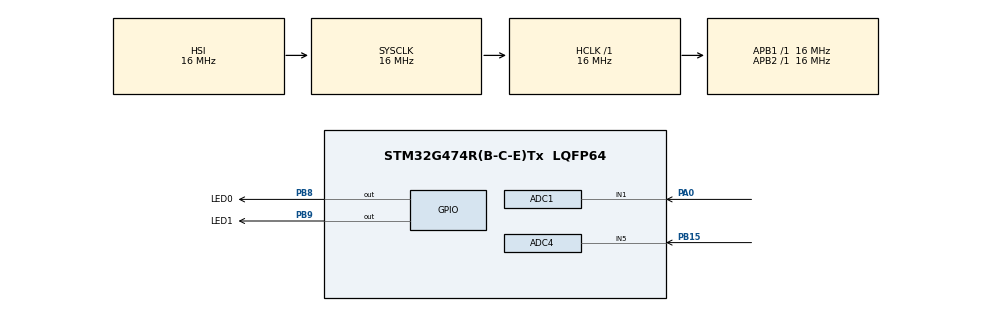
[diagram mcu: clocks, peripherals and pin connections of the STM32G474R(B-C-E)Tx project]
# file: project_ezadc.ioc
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ADC1.Channel-0\#ChannelRegularConversion=ADC_CHANNEL_1
ADC1.NbrOfConversionFlag=1
ADC1.OffsetNumber-0\#ChannelRegularConversion=ADC_OFFSET_NONE
ADC1.Rank-0\#ChannelRegularConversion=1
ADC1.SamplingTime-0\#ChannelRegularConversion=ADC_SAMPLETIME_2CYCLES_5
ADC1.master=1
ADC2.Channel-0\#ChannelRegularConversion=ADC_CHANNEL_1
ADC2.NbrOfConversionFlag=1
ADC2.OffsetNumber-0\#ChannelRegularConversion=ADC_OFFSET_NONE
ADC2.Rank-0\#ChannelRegularConversion=1
ADC2.SamplingTime-0\#ChannelRegularConversion=ADC_SAMPLETIME_2CYCLES_5
ADC4.Channel-0\#ChannelRegularConversion=ADC_CHANNEL_5
ADC4.NbrOfConversionFlag=1
ADC4.OffsetNumber-0\#ChannelRegularConversion=ADC_OFFSET_NONE
ADC4.Rank-0\#ChannelRegularConversion=1
ADC4.SamplingTime-0\#ChannelRegularConversion=ADC_SAMPLETIME_2CYCLES_5
Mcu.Family=STM32G4
Mcu.Name=STM32G474R(B-C-E)Tx
Mcu.Package=LQFP64
NVIC.PriorityGroup=NVIC_PRIORITYGROUP_4
PA0.Signal=SharedAnalog_PA0
PA13.Mode=Serial_Wire
PA13.Signal=SYS_JTMS-SWDIO
PA14.Mode=Serial_Wire
PA14.Signal=SYS_JTCK-SWCLK
PB15.Mode=IN5-Single-Ended
PB15.Signal=ADC4_IN5
PB8-BOOT0.GPIO_Label=LED0
PB8-BOOT0.Signal=GPIO_Output
PB9.GPIO_Label=LED1
PB9.Signal=GPIO_Output
ProjectManager.HeapSize=0x200
ProjectManager.StackSize=0x400
ProjectManager.TargetToolchain=STM32CubeIDE
RCC.AHBFreq_Value=16000000
RCC.APB1Freq_Value=16000000
RCC.APB1TimFreq_Value=16000000
RCC.APB2Freq_Value=16000000
RCC.APB2TimFreq_Value=16000000
RCC.CortexFreq_Value=16000000
RCC.EXTERNAL_CLOCK_VALUE=12288000
RCC.HCLKFreq_Value=16000000
RCC.HSE_VALUE=8000000
RCC.HSI48_VALUE=48000000
RCC.HSI_VALUE=16000000
RCC.LSE_VALUE=32768
RCC.SYSCLKFreq_VALUE=16000000
RCC.USBFreq_Value=64000000
RCC.VCOOutputFreq_Value=128000000
SH.SharedAnalog_PA0.0=ADC1_IN1,IN1-Single-Ended
SH.SharedAnalog_PA0.1=ADC2_IN1,IN1-Single-Ended
VP_SYS_VS_DBSignals.Mode=DisableDeadBatterySignals
board=custom

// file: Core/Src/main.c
/* USER CODE BEGIN Header */
/**
  ******************************************************************************
  * @file           : main.c
  * @brief          : Main program body
  ******************************************************************************
  * @attention
  *
  * Copyright (c) 2024 STMicroelectronics.
  * All rights reserved.
  *
  * This software is licensed under terms that can be found in the LICENSE file
  * in the root directory of this software component.
  * If no LICENSE file comes with this software, it is provided AS-IS.
  *
  ******************************************************************************
  */
/* USER CODE END Header */
#include "main.h"

ADC_HandleTypeDef hadc1;
ADC_HandleTypeDef hadc2;
ADC_HandleTypeDef hadc4;

void SystemClock_Config(void);
static void MX_GPIO_Init(void);
static void MX_ADC1_Init(void);
static void MX_ADC4_Init(void);
static void MX_ADC2_Init(void);

int main(void)
{

  /* MCU Configuration--------------------------------------------------------*/

  /* Reset of all peripherals, Initializes the Flash interface and the Systick. */
  HAL_Init();

  /* Configure the system clock */
  SystemClock_Config();

  /* Initialize all configured peripherals */
  MX_GPIO_Init();
  MX_ADC1_Init();
  MX_ADC4_Init();
  MX_ADC2_Init();

  /* Infinite loop */
  while (1)
  {

    /* USER CODE BEGIN 3 */
	  uint32_t i;
	  int min = 0;
	  int max = 4039;
	  HAL_ADC_Start(&hadc1);
	  HAL_ADC_PollForConversion(&hadc1, 100);
	  i = HAL_ADC_GetValue(&hadc1);
	  if ((int)i > min && (int) i < max / 2)
	  {
		  HAL_GPIO_WritePin(LED0_GPIO_Port, LED0_Pin, GPIO_PIN_SET);
		  HAL_GPIO_WritePin(LED1_GPIO_Port, LED1_Pin, GPIO_PIN_RESET);

	  }
	  else if ((int)i >= max/2 &&(int) i <max)
	  {
		  HAL_GPIO_WritePin(LED0_GPIO_Port, LED0_Pin, GPIO_PIN_RESET);
		  HAL_GPIO_WritePin(LED1_GPIO_Port, LED1_Pin, GPIO_PIN_SET);
	  }

	  HAL_ADC_Stop(&hadc1);

  }
  /* USER CODE END 3 */
}

void SystemClock_Config(void)
{
  RCC_OscInitTypeDef RCC_OscInitStruct = {0};
  RCC_ClkInitTypeDef RCC_ClkInitStruct = {0};

  /** Configure the main internal regulator output voltage
  */
  HAL_PWREx_ControlVoltageScaling(PWR_REGULATOR_VOLTAGE_SCALE1);

  /** Initializes the RCC Oscillators according to the specified parameters
  * in the RCC_OscInitTypeDef structure.
  */
  RCC_OscInitStruct.OscillatorType = RCC_OSCILLATORTYPE_HSI;
  RCC_OscInitStruct.HSIState = RCC_HSI_ON;
  RCC_OscInitStruct.HSICalibrationValue = RCC_HSICALIBRATION_DEFAULT;
  RCC_OscInitStruct.PLL.PLLState = RCC_PLL_NONE;
  if (HAL_RCC_OscConfig(&RCC_OscInitStruct) != HAL_OK)
  {
    Error_Handler();
  }

  /** Initializes the CPU, AHB and APB buses clocks
  */
  RCC_ClkInitStruct.ClockType = RCC_CLOCKTYPE_HCLK|RCC_CLOCKTYPE_SYSCLK
                              |RCC_CLOCKTYPE_PCLK1|RCC_CLOCKTYPE_PCLK2;
  RCC_ClkInitStruct.SYSCLKSource = RCC_SYSCLKSOURCE_HSI;
  RCC_ClkInitStruct.AHBCLKDivider = RCC_SYSCLK_DIV1;
  RCC_ClkInitStruct.APB1CLKDivider = RCC_HCLK_DIV1;
  RCC_ClkInitStruct.APB2CLKDivider = RCC_HCLK_DIV1;

  if (HAL_RCC_ClockConfig(&RCC_ClkInitStruct, FLASH_LATENCY_0) != HAL_OK)
  {
    Error_Handler();
  }
}

static void MX_ADC1_Init(void)
{

  ADC_MultiModeTypeDef multimode = {0};
  ADC_ChannelConfTypeDef sConfig = {0};

  /** Common config
  */
  hadc1.Instance = ADC1;
  hadc1.Init.ClockPrescaler = ADC_CLOCK_SYNC_PCLK_DIV2;
  hadc1.Init.Resolution = ADC_RESOLUTION_12B;
  hadc1.Init.DataAlign = ADC_DATAALIGN_RIGHT;
  hadc1.Init.GainCompensation = 0;
  hadc1.Init.ScanConvMode = ADC_SCAN_DISABLE;
  hadc1.Init.EOCSelection = ADC_EOC_SINGLE_CONV;
  hadc1.Init.LowPowerAutoWait = DISABLE;
  hadc1.Init.ContinuousConvMode = DISABLE;
  hadc1.Init.NbrOfConversion = 1;
  hadc1.Init.DiscontinuousConvMode = DISABLE;
  hadc1.Init.ExternalTrigConv = ADC_SOFTWARE_START;
  hadc1.Init.ExternalTrigConvEdge = ADC_EXTERNALTRIGCONVEDGE_NONE;
  hadc1.Init.DMAContinuousRequests = DISABLE;
  hadc1.Init.Overrun = ADC_OVR_DATA_PRESERVED;
  hadc1.Init.OversamplingMode = DISABLE;
  if (HAL_ADC_Init(&hadc1) != HAL_OK)
  {
    Error_Handler();
  }

  /** Configure the ADC multi-mode
  */
  multimode.Mode = ADC_MODE_INDEPENDENT;
  if (HAL_ADCEx_MultiModeConfigChannel(&hadc1, &multimode) != HAL_OK)
  {
    Error_Handler();
  }

  /** Configure Regular Channel
  */
  sConfig.Channel = ADC_CHANNEL_1;
  sConfig.Rank = ADC_REGULAR_RANK_1;
  sConfig.SamplingTime = ADC_SAMPLETIME_2CYCLES_5;
  sConfig.SingleDiff = ADC_SINGLE_ENDED;
  sConfig.OffsetNumber = ADC_OFFSET_NONE;
  sConfig.Offset = 0;
  if (HAL_ADC_ConfigChannel(&hadc1, &sConfig) != HAL_OK)
  {
    Error_Handler();
  }

}

static void MX_ADC2_Init(void)
{

  ADC_ChannelConfTypeDef sConfig = {0};

  /** Common config
  */
  hadc2.Instance = ADC2;
  hadc2.Init.ClockPrescaler = ADC_CLOCK_SYNC_PCLK_DIV2;
  hadc2.Init.Resolution = ADC_RESOLUTION_12B;
  hadc2.Init.DataAlign = ADC_DATAALIGN_RIGHT;
  hadc2.Init.GainCompensation = 0;
  hadc2.Init.ScanConvMode = ADC_SCAN_DISABLE;
  hadc2.Init.EOCSelection = ADC_EOC_SINGLE_CONV;
  hadc2.Init.LowPowerAutoWait = DISABLE;
  hadc2.Init.ContinuousConvMode = DISABLE;
  hadc2.Init.NbrOfConversion = 1;
  hadc2.Init.DiscontinuousConvMode = DISABLE;
  hadc2.Init.ExternalTrigConv = ADC_SOFTWARE_START;
  hadc2.Init.ExternalTrigConvEdge = ADC_EXTERNALTRIGCONVEDGE_NONE;
  hadc2.Init.DMAContinuousRequests = DISABLE;
  hadc2.Init.Overrun = ADC_OVR_DATA_PRESERVED;
  hadc2.Init.OversamplingMode = DISABLE;
  if (HAL_ADC_Init(&hadc2) != HAL_OK)
  {
    Error_Handler();
  }

  /** Configure Regular Channel
  */
  sConfig.Channel = ADC_CHANNEL_1;
  sConfig.Rank = ADC_REGULAR_RANK_1;
  sConfig.SamplingTime = ADC_SAMPLETIME_2CYCLES_5;
  sConfig.SingleDiff = ADC_SINGLE_ENDED;
  sConfig.OffsetNumber = ADC_OFFSET_NONE;
  sConfig.Offset = 0;
  if (HAL_ADC_ConfigChannel(&hadc2, &sConfig) != HAL_OK)
  {
    Error_Handler();
  }

}

static void MX_ADC4_Init(void)
{

  ADC_ChannelConfTypeDef sConfig = {0};

  /** Common config
  */
  hadc4.Instance = ADC4;
  hadc4.Init.ClockPrescaler = ADC_CLOCK_SYNC_PCLK_DIV2;
  hadc4.Init.Resolution = ADC_RESOLUTION_12B;
  hadc4.Init.DataAlign = ADC_DATAALIGN_RIGHT;
  hadc4.Init.GainCompensation = 0;
  hadc4.Init.ScanConvMode = ADC_SCAN_DISABLE;
  hadc4.Init.EOCSelection = ADC_EOC_SINGLE_CONV;
  hadc4.Init.LowPowerAutoWait = DISABLE;
  hadc4.Init.ContinuousConvMode = DISABLE;
  hadc4.Init.NbrOfConversion = 1;
  hadc4.Init.DiscontinuousConvMode = DISABLE;
  hadc4.Init.ExternalTrigConv = ADC_SOFTWARE_START;
  hadc4.Init.ExternalTrigConvEdge = ADC_EXTERNALTRIGCONVEDGE_NONE;
  hadc4.Init.DMAContinuousRequests = DISABLE;
  hadc4.Init.Overrun = ADC_OVR_DATA_PRESERVED;
  hadc4.Init.OversamplingMode = DISABLE;
  if (HAL_ADC_Init(&hadc4) != HAL_OK)
  {
    Error_Handler();
  }

  /** Configure Regular Channel
  */
  sConfig.Channel = ADC_CHANNEL_5;
  sConfig.Rank = ADC_REGULAR_RANK_1;
  sConfig.SamplingTime = ADC_SAMPLETIME_2CYCLES_5;
  sConfig.SingleDiff = ADC_SINGLE_ENDED;
  sConfig.OffsetNumber = ADC_OFFSET_NONE;
  sConfig.Offset = 0;
  if (HAL_ADC_ConfigChannel(&hadc4, &sConfig) != HAL_OK)
  {
    Error_Handler();
  }

}

static void MX_GPIO_Init(void)
{
  GPIO_InitTypeDef GPIO_InitStruct = {0};

  /* GPIO Ports Clock Enable */
  __HAL_RCC_GPIOA_CLK_ENABLE();
  __HAL_RCC_GPIOB_CLK_ENABLE();

  /*Configure GPIO pin Output Level */
  HAL_GPIO_WritePin(GPIOB, LED0_Pin|LED1_Pin, GPIO_PIN_RESET);

  /*Configure GPIO pins : LED0_Pin LED1_Pin */
  GPIO_InitStruct.Pin = LED0_Pin|LED1_Pin;
  GPIO_InitStruct.Mode = GPIO_MODE_OUTPUT_PP;
  GPIO_InitStruct.Pull = GPIO_NOPULL;
  GPIO_InitStruct.Speed = GPIO_SPEED_FREQ_LOW;
  HAL_GPIO_Init(GPIOB, &GPIO_InitStruct);

}

void Error_Handler(void)
{
  __disable_irq();
  while (1)
  {
  }
}
